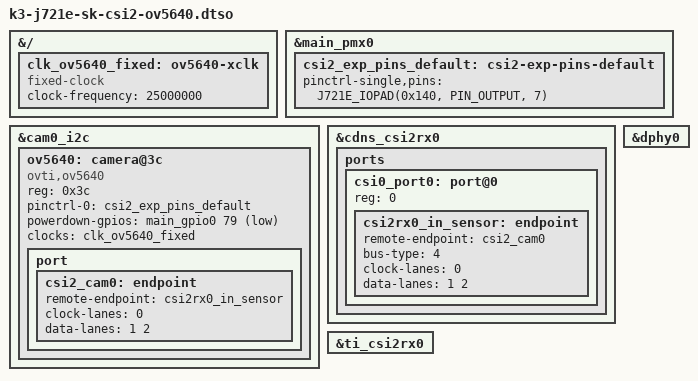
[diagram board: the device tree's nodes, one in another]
// SPDX-License-Identifier: GPL-2.0
/*
 * LI OV5640 MIPI Camera module on MIPI CSI connector.
 *
 * Copyright (C) 2024 Texas Instruments Incorporated - https://www.ti.com/
 */

/dts-v1/;
/plugin/;

#include <dt-bindings/gpio/gpio.h>
#include "k3-pinctrl.h"

&{/} {
	clk_ov5640_fixed: ov5640-xclk {
		compatible = "fixed-clock";
		#clock-cells = <0>;
		clock-frequency = <25000000>;
	};
};

&main_pmx0 {
	csi2_exp_pins_default: csi2-exp-pins-default {
		pinctrl-single,pins = <
			J721E_IOPAD(0x140, PIN_OUTPUT, 7) /* (AG29) PRG0_PRU1_GPO16.GPIO0_79 */
		>;
	};
};

&cam0_i2c {
	#address-cells = <1>;
	#size-cells = <0>;

	ov5640: camera@3c {
		compatible = "ovti,ov5640";
		reg = <0x3c>;
		pinctrl-names = "default";
		pinctrl-0 = <&csi2_exp_pins_default>;
		powerdown-gpios = <&main_gpio0 79 GPIO_ACTIVE_LOW>;
		clocks = <&clk_ov5640_fixed>;
		clock-names = "xclk";

		port {
			csi2_cam0: endpoint {
				remote-endpoint = <&csi2rx0_in_sensor>;
				clock-lanes = <0>;
				data-lanes = <1 2>;
			};
		};
	};
};

&cdns_csi2rx0 {
	ports {
		#address-cells = <1>;
		#size-cells = <0>;

		csi0_port0: port@0 {
			reg = <0>;
			status = "okay";

			csi2rx0_in_sensor: endpoint {
				remote-endpoint = <&csi2_cam0>;
				bus-type = <4>; /* CSI2 DPHY */
				clock-lanes = <0>;
				data-lanes = <1 2>;
			};
		};
	};
};

&ti_csi2rx0 {
	status = "okay";
};

&dphy0 {
	status = "okay";
};
